# STM32MP25_CM33 register map
File version: 1.3
CPU: CM33 r0p1, little endian, MPU, FPU, vendor SysTick, 8 interrupt priority bits
Registers are 32-bit, read-write, reset 0x0 unless marked. A register's access mark holds for its fields unless they carry their own. Offsets are from the block's base; [hi:lo] are bit positions; {n}, {i} and the like mark numbered series; 'fields as' and 'values as' point back to an identical list.

## SYSCFG — SYSCFG register block
Base 0x44230000
Same registers: SYSCFG_S 0x54230000
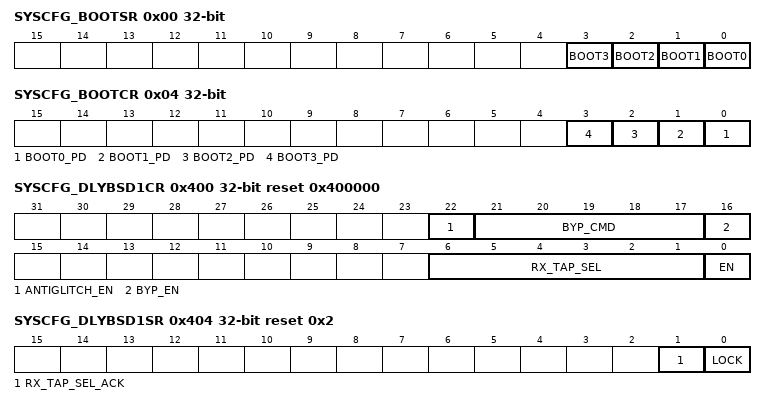
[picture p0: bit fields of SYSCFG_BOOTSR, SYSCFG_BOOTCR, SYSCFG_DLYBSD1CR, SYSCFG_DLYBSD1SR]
0x00 SYSCFG_BOOTSR ro (reset mask 0xFFFFFFF0) — SYSCFG boot pin status register
  [n] BOOT{n} (n=0..3) — BOOT{n} pin value
    0=low (BOOT{n} pin connected to VSS (or left open if BOOT{n}_PD = 0)); 1=high (BOOT{n} pin connected to VDD)
0x04 SYSCFG_BOOTCR — SYSCFG boot pin control register
  [all] fields
    0=enabled (pull-down enabled.); 1=disabled (pull-down disabled.)
  [n] BOOT{n}_PD (n=0..3) — BOOT{n} pin pull-down disable
0x400 SYSCFG_DLYBSD1CR reset 0x400000 — SYSCFG DLYBSD1 control register
  [22] ANTIGLITCH_EN
    1=The anti-glitch logic is enabled
  [21:17] BYP_CMD — Delay unit when in DLL bypass mode
    1=1 delay element enabled; 2=2 delay elements enabled; 24=all 24 delay elements enabled; 25=all 24 delay elements enabled; 31=all 24 delay elements enabled
  [16] BYP_EN — DLL bypass mode enable
    1=DLL bypass mode is enabled; 0=DLL lock mode is selected
  [6:1] RX_TAP_SEL — TAP number for RX clock selection
    0=0 tap selected; 1=1 tap is selected; 2=2 taps selected; 31=31 taps selected; 32=32 taps selected
  [0] EN — When 1, the DLL is enabled when configured in lock mode (BYP_EN = 0).
0x404 SYSCFG_DLYBSD1SR ro reset 0x2 — SYSCFG DLYBSD1 status register
  [1] RX_TAP_SEL_ACK
    1=The RX delay switched to the tap value specified in RX_TAP_SEL[5:0]
  [0] LOCK
    1=The DLL is locked
0x408 SYSCFG_SDMMC1CR — SYSCFG SDMMC1 control register
  [0] SDMMC1_VSEL — Voltage selection
    1=Change the voltage to low-voltage range (1; 0=Change the voltage to high-voltage range (3
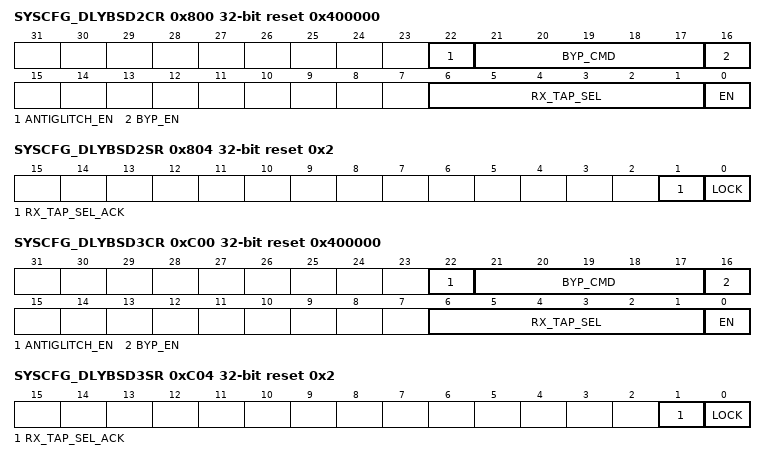
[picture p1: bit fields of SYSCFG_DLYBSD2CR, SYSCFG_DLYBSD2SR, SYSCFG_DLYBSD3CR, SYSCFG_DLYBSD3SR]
0x800 SYSCFG_DLYBSD2CR reset 0x400000 — SYSCFG DLYBSD2 control register
  [22] ANTIGLITCH_EN — Anti-glitch logic enable
    1=The anti-glitch logic is enabled
  [21:17] BYP_CMD — Delay unit when in DLL bypass mode
    values as SYSCFG_DLYBSD1CR.BYP_CMD
  [16] BYP_EN — DLL bypass mode enable
    1=DLL bypass mode is enabled; 0=DLL lock mode is selected
  [6:1] RX_TAP_SEL — TAP delay for RX clock selection
    0=0 tap selected; 1=1 tap selected; 2=2 taps selected; 31=31 taps selected; 32=32 taps selected
  [0] EN
    1=The DLL is enabled when configured in lock mode (BYP_EN = 0)
0x804 SYSCFG_DLYBSD2SR ro reset 0x2 — SYSCFG DLYBSD2 status register
  fields as SYSCFG_DLYBSD1SR
0x808 SYSCFG_SDMMC2CR — SYSCFG SDMMC2 control register
  [0] SDMMC2_VSEL — Voltage selection
    values as SYSCFG_SDMMC1CR.SDMMC1_VSEL
0xC00 SYSCFG_DLYBSD3CR reset 0x400000 — SYSCFG DLYBSD3 control register
  fields as SYSCFG_DLYBSD2CR
0xC04 SYSCFG_DLYBSD3SR ro reset 0x2 — SYSCFG DLYBSD3 status register
  [1] RX_TAP_SEL_ACK
    1=The RX delay has switched to the tap value specified in RX_TAP_SEL[5:0]
  [0] LOCK
    1=The DLL is locked
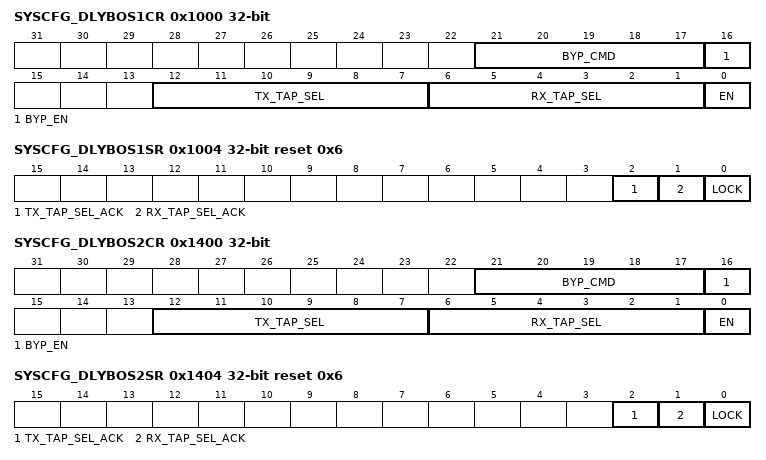
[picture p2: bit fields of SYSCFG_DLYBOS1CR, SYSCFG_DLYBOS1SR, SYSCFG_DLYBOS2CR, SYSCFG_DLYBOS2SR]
0x1000 SYSCFG_DLYBOS1CR — SYSCFG DLYBOS1 control register
  [21:17] BYP_CMD — Delay unit when in DLL bypass mode
    values as SYSCFG_DLYBSD1CR.BYP_CMD
  [16] BYP_EN — DLL bypass mode enable
    1=DLL bypass mode is enabled; 0=DLL lock mode is selected
  [12:7] TX_TAP_SEL — TAP delay for TX clock selection
    values as SYSCFG_DLYBSD2CR.RX_TAP_SEL
  [6:1] RX_TAP_SEL — TAP delay for RX clock selection
    values as SYSCFG_DLYBSD2CR.RX_TAP_SEL
  [0] EN
    values as SYSCFG_DLYBSD2CR.EN
0x1004 SYSCFG_DLYBOS1SR ro reset 0x6 — SYSCFG DLYBOS1 status register
  [2] TX_TAP_SEL_ACK
    1=The TX delay has switched to the tap value specified in TX_TAP_SEL[5:0]
  [1] RX_TAP_SEL_ACK
    values as SYSCFG_DLYBSD3SR.RX_TAP_SEL_ACK
  [0] LOCK
    1=The DLL is locked
0x1400 SYSCFG_DLYBOS2CR — SYSCFG DLYBOS2 control register
  [21:17] BYP_CMD — Delay unit when in DLL bypass mode
    values as SYSCFG_DLYBSD1CR.BYP_CMD
  [16] BYP_EN — DLL bypass mode enable
    1=DLL bypass mode is enabled; 0=DLL lock mode is selected
  [12:7] TX_TAP_SEL — TAP delay for TX clock selection
    values as SYSCFG_DLYBSD2CR.RX_TAP_SEL
  [6:1] RX_TAP_SEL — TAP delay for RX clock selection
    0=0 tap selected; 1=1 tap selected; 2=2 taps selected; 31=31 taps are selected; 32=32 taps are selected
  [0] EN — e
    values as SYSCFG_DLYBSD2CR.EN
0x1404 SYSCFG_DLYBOS2SR ro reset 0x6 — SYSCFG DLYBOS2 status register
  fields as SYSCFG_DLYBOS1SR
0x1800 SYSCFG_VDERAMCR — SYSCFG video decoder encoder RAM control register
  [0] VDERAM_EN — VDEC/VENC RAM enable
    0=VDERAM not allocated to the system; 1=VDERAM allocated to the system
0x1804 SYSCFG_POTTAMPRSTCR — SYSCFG potential tamper reset control register
  [0] POTTAMPRESETMASK — This bit can be set by software to mask PKA, SAES, CRYP1/2, and HASH reset in case of potential tamper.
    0=PKA, SAES, CRYP1/2, and HASH reset in case of potential tamper; 1=PKA, SAES, CRYP1/2, and HASH not reset in case of potential tamper
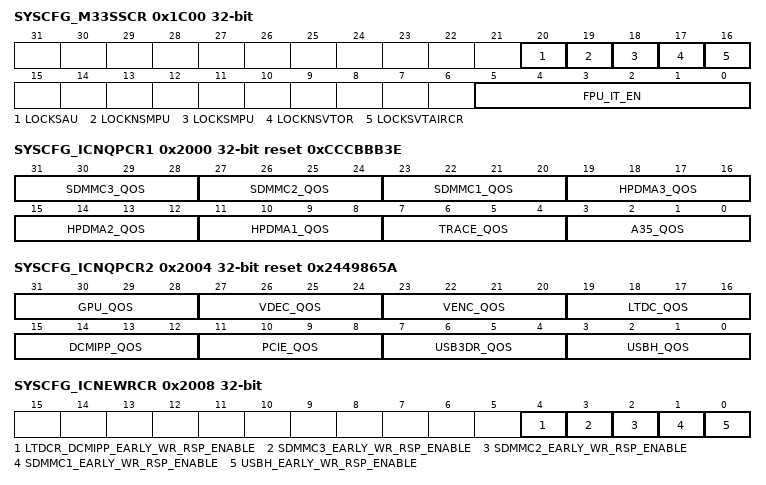
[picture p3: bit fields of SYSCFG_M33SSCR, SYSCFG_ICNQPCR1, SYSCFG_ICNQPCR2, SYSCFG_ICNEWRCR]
0x1C00 SYSCFG_M33SSCR — SYSCFG M33SS control register
  [20] LOCKSAU — Prevent changes to secure SAU memory regions already programmed.
  [19] LOCKNSMPU — Prevent changes to non-secure MPU memory regions already programmed.
  [18] LOCKSMPU — Prevent changes to programmed secure MPU memory regions.
  [17] LOCKNSVTOR — Prevent changes to non-secure vector table base address.
  [16] LOCKSVTAIRCR — Prevent changes to:
  [5:0] FPU_IT_EN — Floating point unit interrupt enable
0x2000 SYSCFG_ICNQPCR1 reset 0xCCCBBB3E — SYSCFG ICN QOS priority control register 1
  [all] fields
    0=Lowest priority; 15=Highest priority
  [31:28] SDMMC3_QOS — SDMMC3 read/write channel QoS setting
  [27:24] SDMMC2_QOS — SDMMC2 read/write channes QoS setting
  [23:20] SDMMC1_QOS — SDMMC1 read/write channel QoS setting
  [19:16] HPDMA3_QOS — HPDMA3 read/write channel QoS setting
  [15:12] HPDMA2_QOS — HPDMA2 read/write channel QoS setting
  [11:8] HPDMA1_QOS — HPDMA1 read/write channel QoS setting
  [7:4] TRACE_QOS — TRACE read/write channel QoS setting
  [3:0] A35_QOS — Cortex-A35 read/write channel QoS setting
0x2004 SYSCFG_ICNQPCR2 reset 0x2449865A — SYSCFG ICN QOS priority control register 2
  [all] fields
    0=Lowest priority; 15=Highest priority
  [31:28] GPU_QOS — GPU read/write channel QoS setting
  [27:24] VDEC_QOS — VDEC read/write channels QoS setting
  [23:20] VENC_QOS — VENC read/write channels QoS setting
  [19:16] LTDC_QOS — LTDC read/write channels QoS setting
  [15:12] DCMIPP_QOS — DCMIPP write channel QoS setting
  [11:8] PCIE_QOS — PCIE read/write channel QoS setting
  [7:4] USB3DR_QOS — USB3DR read/write channel QoS setting
  [3:0] USBH_QOS — USBH read/write channel QoS setting
0x2008 SYSCFG_ICNEWRCR — SYSCFG ICN early write response control register
  [all] fields
    0=Early write response disabled; 1=Early write response enabled
  [4] LTDCR_DCMIPP_EARLY_WR_RSP_ENABLE — LTDC Rotation and DCMIPP early write response enable
  [3] SDMMC3_EARLY_WR_RSP_ENABLE — SDMMC3 early write response enable
  [2] SDMMC2_EARLY_WR_RSP_ENABLE — SDMMC2 early write response enable
  [1] SDMMC1_EARLY_WR_RSP_ENABLE — SDMMC1 early write response enable
  [0] USBH_EARLY_WR_RSP_ENABLE — USBH (OHCI and EHCI) early write response enable
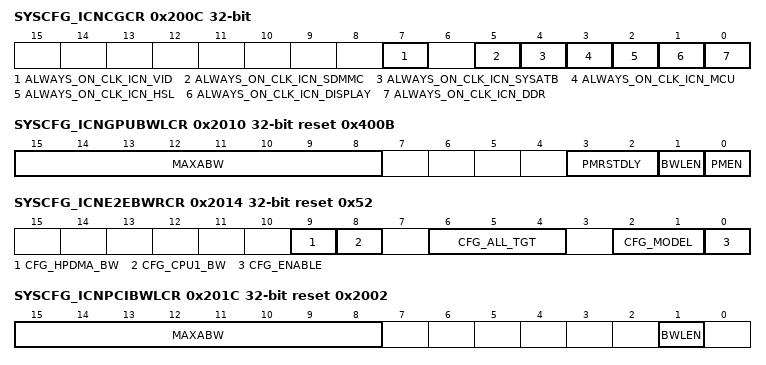
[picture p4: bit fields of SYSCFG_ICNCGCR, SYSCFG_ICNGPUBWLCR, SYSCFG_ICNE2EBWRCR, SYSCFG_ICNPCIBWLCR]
0x200C SYSCFG_ICNCGCR — SYSCFG ICN clock gating control register
  [7] ALWAYS_ON_CLK_ICN_VID — When set to 1, ICN automatic clock gating on clk_icn_vid domain is off.
  [5] ALWAYS_ON_CLK_ICN_SDMMC — When set to 1, ICN automatic clock gating on clk_icn_sdmmc domain is off.
  [4] ALWAYS_ON_CLK_ICN_SYSATB — When set to 1, ICN automatic clock gating on clk_icn_sysatb domain is off.
  [3] ALWAYS_ON_CLK_ICN_MCU — When set to 1, ICN automatic clock gating on clk_icn_mcu domain is off.
  [2] ALWAYS_ON_CLK_ICN_HSL — When set to 1, ICN automatic clock gating on clk_icn_hsl domain is off.
  [1] ALWAYS_ON_CLK_ICN_DISPLAY — When set to 1, ICN automatic clock gating on clk_icn_display domain is off.
  [0] ALWAYS_ON_CLK_ICN_DDR — When set to 1, ICN automatic clock gating on clk_icn_ddr domain is off.
0x2010 SYSCFG_ICNGPUBWLCR reset 0x400B — SYSCFG ICN GPU bandwidth limiter control register
  [15:8] MAXABW — Maximum allowed Bandwidth
    1=Bandwidth limited at 1/128 of 9
  [3:2] PMRSTDLY — Panic Mode Restart Delay
    0=No delay (immediate restart of flow); 1=16-cycle delay at DDR-CTRL frequency; 2=32-cycle delay at DDR-CTRL frequency; 3=64-cycle delay at DDR-CTRL frequency
  [1] BWLEN — Bandwidth limiter enable
    0=Bandwidth limiter disabled; 1=Bandwidth limiter enabled
  [0] PMEN — Panic Mode Enable
    0=DDR-to-GPU regulation disabled; 1=DDR-to-GPU regulation enabled
0x2014 SYSCFG_ICNE2EBWRCR reset 0x52 — SYSCFG ICN end-to-end bandwidth regulation control register
  [9] CFG_HPDMA_BW — Triple the bandwidth (BW) allowed to HPDMA1/2/3 by the regulation.
    0=Normal bandwidth allocated to HPDMA1/2/3; 1=Increased bandwidth allocated to HPDMA1/2/3
  [8] CFG_CPU1_BW — Triple the bandwidth allowed to the CPU1 by the regulation.
    values as CFG_HPDMA_BW
  [6:4] CFG_ALL_TGT — Amount of empty CAM slots in DDR-CTRL that the regulation targets
    0=9 empty slots targeted; 1=11 empty slots targeted; 2=13 empty slots targeted; 3=15 empty slots targeted; 4=17 empty slots targeted; 5=20 empty slots targeted (default); 6=24 empty slots targeted; 7=28 empty slots targeted
  [2:1] CFG_MODEL — Defines the reactivity of the regulation feedback.
    0=Slow reaction (risk of congestion if the regulation reacts too slow); 3=Fast reaction (risk of oscillation if the regulation reacts too fast)
  [0] CFG_ENABLE — Activates the end-to-end bandwidth regulation.
    0=Regulation disabled; 1=Regulation enabled
0x2018 SYSCFG_SAFERSTCR — SYSCFG safe reset control register
  [0] CFG_ENABLE — Activates the safe reset connector.
    0=Safe reset connector disabled; 1=Safe reset connector enabled
0x201C SYSCFG_ICNPCIBWLCR reset 0x2002 — SYSCFG ICN PCI bandwidth limiter control register
  [15:8] MAXABW — Maximum allowed Bandwidth
    1=Bandwidth limited at 1/128 of 2
  [1] BWLEN — Bandwidth limiter enable
    0=Bandwidth limiter disabled; 1=Bandwidth limiter enabled
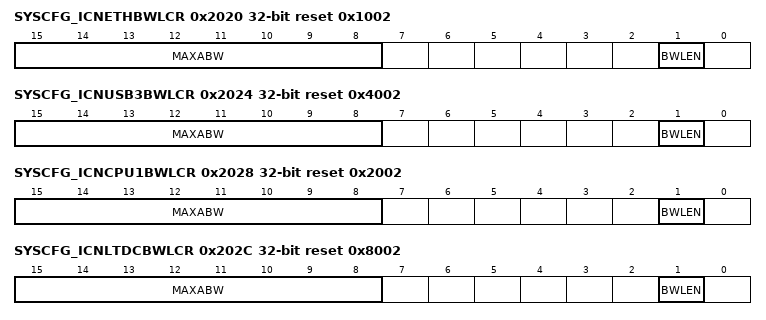
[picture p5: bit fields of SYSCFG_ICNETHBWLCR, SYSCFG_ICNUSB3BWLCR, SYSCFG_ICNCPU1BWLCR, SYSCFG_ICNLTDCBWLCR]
0x2020 SYSCFG_ICNETHBWLCR reset 0x1002 — SYSCFG ICN ETH bandwidth limiter control register
  fields as SYSCFG_ICNPCIBWLCR
0x2024 SYSCFG_ICNUSB3BWLCR reset 0x4002 — SYSCFG ICN USB3 bandwidth limiter control register
  fields as SYSCFG_ICNPCIBWLCR
0x2028 SYSCFG_ICNCPU1BWLCR reset 0x2002 — SYSCFG ICN CPU1 bandwidth limiter control register
  [15:8] MAXABW — Maximum allowed Bandwidth
    1=Bandwidth limited at 1/128 of 9
  [1] BWLEN — Bandwidth limiter enable
    0=Bandwidth limiter disabled; 1=Bandwidth limiter enabled
0x202C SYSCFG_ICNLTDCBWLCR reset 0x8002 — SYSCFG ICN LTDC bandwidth limiter control register
  [15:8] MAXABW — Maximum allowed Bandwidth
    1=Bandwidth limited at 1/128 of 3
  [1] BWLEN — Bandwidth limiter enable
    0=Bandwidth limiter disabled; 1=Bandwidth limiter enabled
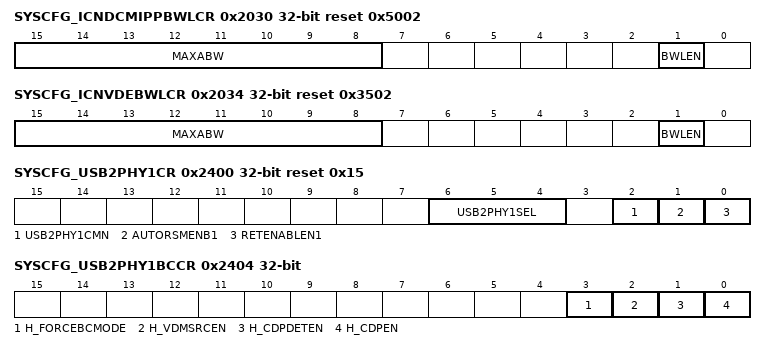
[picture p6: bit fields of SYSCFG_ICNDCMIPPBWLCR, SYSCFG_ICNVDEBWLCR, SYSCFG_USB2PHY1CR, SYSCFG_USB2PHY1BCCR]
0x2030 SYSCFG_ICNDCMIPPBWLCR reset 0x5002 — SYSCFG ICN DCMIPP bandwidth limiter control register
  fields as SYSCFG_ICNLTDCBWLCR
0x2034 SYSCFG_ICNVDEBWLCR reset 0x3502 — SYSCFG ICN Video Decoder Encoder bandwidth limiter control register
  [15:8] MAXABW — Maximum allowed Bandwidth
    1=Bandwidth limited at 1/128 of 4
  [1] BWLEN — Bandwidth limiter enable
    0=Bandwidth limiter disabled; 1=Bandwidth limiter enabled
0x2400 SYSCFG_USB2PHY1CR reset 0x15 — SYSCFG USB2PHY1 control register
  [6:4] USB2PHY1SEL — PHY reference clock speed setting
    0=19; 1=20 MHz (default); 2=24 MHz
  [2] USB2PHY1CMN — Controls power down of analog blocks during Suspend and Sleep.
    0=PHY clocks are kept active during Suspend and Sleep (with the exception of PHYCLK); 1=PHY clocks are off during Suspend and Sleep
  [1] AUTORSMENB1 — Auto-resume mode enable
    0=Auto-resume disabled (default; 1=A pulse on this bit prior to enabling the retention mode, enables the auto-resume mode
  [0] RETENABLEN1 — Retention mode enable (active low)
    0=Retention mode enabled; 1=Retention mode disabled (default)
0x2404 SYSCFG_USB2PHY1BCCR — SYSCFG USB2PHY1 battery charging control register
  [3] H_FORCEBCMODE — Forces USB2PHY1 in non-driving suspend mode.
    0=Normal mode; 1=OPMODE0[1:0] is forced to non-driving, and SUSPENDM0 is forced to active
  [2] H_VDMSRCEN — Voltage source on DM for CDP port enable
    0=Voltage source disabled (default); 1=Voltage source enabled
  [1] H_CDPDETEN — Voltage detector on DP for CDP port enable
    0=voltage detector on DP disabled (default); 1=voltage detector on DP enabled
  [0] H_CDPEN — CDP behavior for Host port enable
    0=CDP behavior disabled (Host port behaves as an SDP) (default); 1=CDP behavior enabled
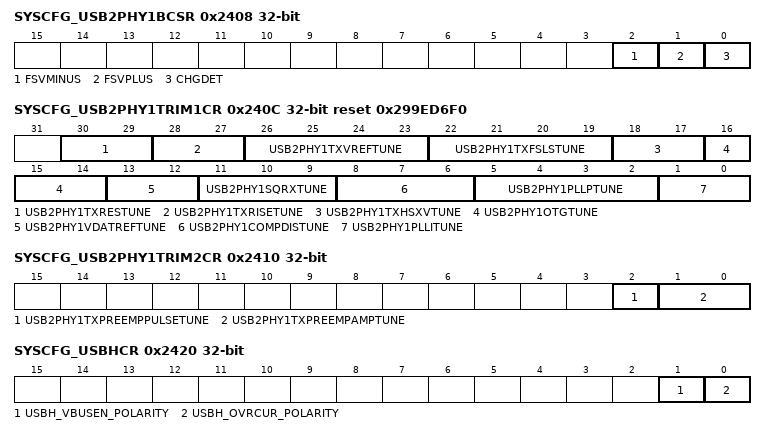
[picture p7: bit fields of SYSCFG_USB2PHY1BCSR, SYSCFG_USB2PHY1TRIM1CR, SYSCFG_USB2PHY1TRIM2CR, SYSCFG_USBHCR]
0x2408 SYSCFG_USB2PHY1BCSR ro — SYSCFG USB2PHY1 battery charging status register
  [2] FSVMINUS — Voltage level on DM (also output of the comparison with VLGC threshold, as defined in BC v1.
    0=VDM less than VLGC; 1=VDM > VLGC
  [1] FSVPLUS — Voltage level on DP (also output of the comparison with VLGC threshold, as defined in BC v1.
    0=VDP less than VLGC; 1=VDP > VLGC
  [0] CHGDET — Comparison of voltage on DP with VDAT_REF threshold as defined in BC v1.
    0=VDP less than VDAT_REF; 1=VDP > VDAT_REF
0x240C SYSCFG_USB2PHY1TRIM1CR reset 0x299ED6F0 — SYSCFG USB2PHY1 trimming 1 control register
  [30:29] USB2PHY1TXRESTUNE — USB source impedance adjustment
    3=Source impedance decreased by approximately 5; 2=Source impedance decreased by approximately 3; 1=Nominal; 0=Source impedance increased by approximately 1
  [28:27] USB2PHY1TXRISETUNE — High-speed transmitter rise/fall time adjustment
    3=-8; 2=-7; 1=Nominal; 0=+5
  [26:23] USB2PHY1TXVREFTUNE — HS DC voltage level adjustment
    15=+24%; 14=+22%; 13=+20%; 12=+18%; 11=+16%; 10=+14%; 9=+12%; 8=+10%; 7=+8%; 6=+6%; 5=+4%; 4=+2%; 3=Nominal; 2=-2%; 1=-4%; 0=-6%
  [22:19] USB2PHY1TXFSLSTUNE — Full-speed (FS)/low-speed (LS) source impedance adjustment
    15=-10; 7=-5; 3=Nominal; 1=+6; 0=+14%
  [18:17] USB2PHY1TXHSXVTUNE — Transmitter high-speed crossover adjustment
    3=Nominal; 2=+15 mV; 1=-15 mV
  [16:14] USB2PHY1OTGTUNE — Vless thansub>BUSless than/sub> valid threshold adjustment
    7=+12%; 6=+9%; 5=+6%; 4=+3%; 3=Nominal; 2=-3%; 1=-6%; 0=-9%
  [13:12] USB2PHY1VDATREFTUNE — Data detect voltage adjustment
    3=-20%; 2=-10%; 1=Nominal; 0=+10%
  [11:9] USB2PHY1SQRXTUNE — Squelch threshold adjustment
    7=-20%; 6=-15%; 5=-10%; 4=-5%; 3=Nominal; 2=+5%; 1=+10%; 0=+15%
  [8:6] USB2PHY1COMPDISTUNE — Disconnect threshold adjustment
    7=+12%; 6=+10%; 5=+7%; 4=+3%; 3=Nominal; 2=-4%; 1=-6%; 0=-9%
  [5:2] USB2PHY1PLLPTUNE — PLL proportional path tune
    15=5; 14=5x; 13=4; 12=4x; 11=4; 10=4x; 9=3; 8=3x; 7=3; 6=3x; 5=2; 4=2x; 3=2; 2=2x; 1=1; 0=1x
  [1:0] USB2PHY1PLLITUNE — PLL integral path tune
    3=2; 2=1; 1=1; 0=0
0x2410 SYSCFG_USB2PHY1TRIM2CR — SYSCFG USB2PHY1 trimming 2 control register
  [2] USB2PHY1TXPREEMPPULSETUNE — HS transmitter preemphasis duration control
    1=1x, short pre-emphasis current duration; 0=2x, long pre-emphasis current duration
  [1:0] USB2PHY1TXPREEMPAMPTUNE — HS transmitter preemphasis current control
    3=HS transmitter preemphasis circuit sources 3x preemphasis current; 2=HS transmitter preemphasis circuit sources 2x preemphasis current; 1=HS transmitter preemphasis circuit sources 1x preemphasis current; 0=HS transmitter preemphasis disabled
0x2420 SYSCFG_USBHCR — SYSCFG USBH control register
  [1] USBH_VBUSEN_POLARITY — Polarity of USBH_VBUSEN alternate function
    0=USBH_VBUSEN active high (a 1 logic level means VBUS must be enabled) (default); 1=USBH_VBUSEN active low (a 0 logic level means VBUS must be enabled)
  [0] USBH_OVRCUR_POLARITY — Polarity of USBH_OVRCUR alternate function
    0=USBH_OVRCUR active high (a 1 logic level means there is an over-current situation) (default); 1=USBH_OVRCUR active low (a 0 logic level means there is an over-current situation)
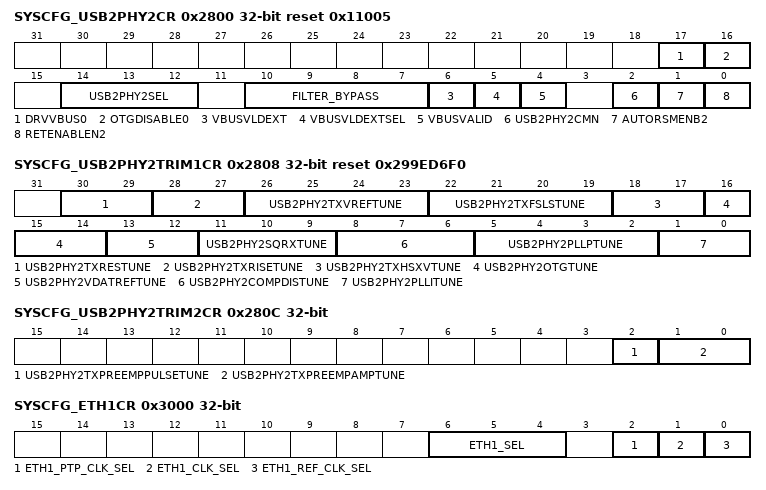
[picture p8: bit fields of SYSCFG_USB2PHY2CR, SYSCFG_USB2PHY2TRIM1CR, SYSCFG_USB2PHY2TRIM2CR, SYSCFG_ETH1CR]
0x2800 SYSCFG_USB2PHY2CR reset 0x11005 — SYSCFG USB2PHY2 control register
  [17] DRVVBUS0 — Control bit for VBUS valid comparator in USB2PHY2
    0=VBUS valid comparator is off in Suspend and Sleep modes (default); 1=VBUS valid comparator is on in Suspend and Sleep modes
  [16] OTGDISABLE0 — Disable control bit for VBUS valid comparator in USB2PHY2
    0=VBUS valid comparator is on in normal mode; 1=VBUS valid comparator is powered down
  [14:12] USB2PHY2SEL — PHY reference clock speed setting
    0=19; 1=20 MHz (default); 2=24 MHz
  [10:7] FILTER_BYPASS — Internal debounce logic enable (default)
    1=internal debounce logic disabled
  [6] VBUSVLDEXT — Voltage comparison result when an external voltage comparator is used
    0=VBUS not valid (default); 1=VBUS above valid threshold
  [5] VBUSVLDEXTSEL — VBUS valid comparator used when USB3DR controller is in device mode
    0=Session valid comparator inside USB2PHY2 is used (default); 1=An external voltage comparator is used
  [4] VBUSVALID — Control of VBUS valid input of USB3DR controller when in Host mode
    0=VBUS not valid (default); 1=VBUS above valid threshold
  [2] USB2PHY2CMN — Control of power down of analog blocks during Suspend and Sleep
    values as SYSCFG_USB2PHY1CR.USB2PHY1CMN
  [1] AUTORSMENB2 — Auto-resume mode enable
    0=Auto-resume is disabled (default); 1=A pulse on this bit prior to enabling the retention mode, enables the auto-resume mode
  [0] RETENABLEN2 — Retention mode enable (active low)
    values as SYSCFG_USB2PHY1CR.RETENABLEN1
0x2808 SYSCFG_USB2PHY2TRIM1CR reset 0x299ED6F0 — SYSCFG USB2PHY2 trimming 1 control register
  [30:29] USB2PHY2TXRESTUNE — USB source impedance adjustment
    values as SYSCFG_USB2PHY1TRIM1CR.USB2PHY1TXRESTUNE
  [28:27] USB2PHY2TXRISETUNE — HS transmitter rise/fall time adjustment
    3=-8; 2=-7; 1=Nominal; 0=+5
  [26:23] USB2PHY2TXVREFTUNE — HS DC voltage level adjustment
    values as SYSCFG_USB2PHY1TRIM1CR.USB2PHY1TXVREFTUNE
  [22:19] USB2PHY2TXFSLSTUNE — Full-speed (FS)/low-speed (LS) source impedance adjustment
    15=-10; 7=-5; 3=Nominal; 1=+6; 0=+14%
  [18:17] USB2PHY2TXHSXVTUNE — Transmitter HS crossover adjustment
    3=Nominal; 2=+15 mV; 1=-15 mV
  [16:14] USB2PHY2OTGTUNE — VBUS valid threshold adjustment
    7=+12%; 6=+9%; 5=+6%; 4=+3%; 3=Nominal; 2=-3%; 1=-6%; 0=-9%
  [13:12] USB2PHY2VDATREFTUNE — Data detect voltage adjustment
    3=-20%; 2=-10%; 1=Nominal; 0=+10%
  [11:9] USB2PHY2SQRXTUNE — Squelch threshold adjustment
    values as SYSCFG_USB2PHY1TRIM1CR.USB2PHY1SQRXTUNE
  [8:6] USB2PHY2COMPDISTUNE — Disconnect threshold adjustment
    7=+12%; 6=+10%; 5=+7%; 4=+3%; 3=Nominal; 2=-4%; 1=-6%; 0=-9%
  [5:2] USB2PHY2PLLPTUNE — PLL proportional path tune
    values as SYSCFG_USB2PHY1TRIM1CR.USB2PHY1PLLPTUNE
  [1:0] USB2PHY2PLLITUNE — PLL integral path tune
    3=2; 2=1; 1=1; 0=0
0x280C SYSCFG_USB2PHY2TRIM2CR — SYSCFG USB2PHY2 trimming 2 control register
  [2] USB2PHY2TXPREEMPPULSETUNE — HS transmitter preemphasis duration control
    1=1x, short preemphasis current duration; 0=2x, long preemphasis current duration
  [1:0] USB2PHY2TXPREEMPAMPTUNE — HS transmitter preemphasis current control
    3=HS transmitter preemphasis circuit sources 3x preemphasis current; 2=HS transmitter preemphasis circuit sources 2x preemphasis current; 1=HS transmitter preemphasis circuit sources 1x preemphasis current; 0=HS transmitter preemphasis is disabled
0x2C00 SYSCFG_OCTOSPIAMCR — SYSCFG OCTOSPI address mapping control register
  [2:0] OCTOSPI_ADDRESS_MAPPING — OCTOSPI1 and OCTOSPI2 address mapping
    0=OCTOSPI1 (256 Mbytes), OCTOSPI2 unmapped; 1=OCTOSPI1 (192 Mbytes), OCTOSPI2 (64 Mbytes); 2=OCTOSPI1 (128 Mbytes), OCTOSPI2 (128 Mbytes); 3=OCTOSPI1 (64 Mbytes), OCTOSPI2 (192 Mbytes)
0x3000 SYSCFG_ETH1CR — SYSCFG Ethernet1 control register
  [6:4] ETH1_SEL — Ethernet 1 PHY interface selection
    0=MII; 1=RGMII; 4=RMII
  [2] ETH1_PTP_CLK_SEL — PTP (IEEE1588) clock selection
    0=ETHSW ptp ref clock is used; 1=ck_ker_eth1ptp from the RCC is used
  [1] ETH1_CLK_SEL — RGMII 125 MHz clock selection
    0=External clock (ETH1_CLK125) is used; 1=Internal clock from the RCC is used
  [0] ETH1_REF_CLK_SEL — Ethernet reference/RX clock selection
    0=External clock is used; 1=Internal clock from the RCC is used
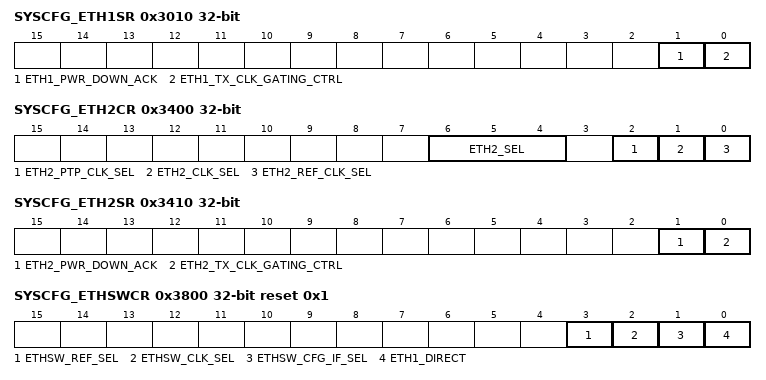
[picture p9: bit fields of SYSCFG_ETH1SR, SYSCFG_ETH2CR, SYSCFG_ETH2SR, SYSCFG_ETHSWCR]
0x3010 SYSCFG_ETH1SR ro — SYSCFG Ethernet1 status register
  [1] ETH1_PWR_DOWN_ACK — Asserted when the power-down sequence start has been acknowledged
  [0] ETH1_TX_CLK_GATING_CTRL — Asserted when the MAC has entered Tx LPI mode
0x3400 SYSCFG_ETH2CR — SYSCFG Ethernet2 configuration register
  [6:4] ETH2_SEL — Ethernet 2 PHY interface selection
    0=MII; 1=RGMII; 4=RMII
  [2] ETH2_PTP_CLK_SEL — PTP (IEEE1588) clock selection
    0=ETHSW ptp ref clock is used; 1=ck_ker_eth2ptp from the RCC is used
  [1] ETH2_CLK_SEL — RGMII 125MHz clock selection
    0=External clock (ETH2_CLK125) is used; 1=Internal clock from the RCC is used
  [0] ETH2_REF_CLK_SEL — Reference/RX clock selection
    values as SYSCFG_ETH1CR.ETH1_REF_CLK_SEL
0x3410 SYSCFG_ETH2SR ro — SYSCFG Ethernet2 status register
  [1] ETH2_PWR_DOWN_ACK — Asserted when the power-down sequence start has been acknowledged
  [0] ETH2_TX_CLK_GATING_CTRL — Asserted when the MAC has entered Tx LPI mode
0x3800 SYSCFG_ETHSWCR reset 0x1 — SYSCFG Ethernet switch configuration register
  [3] ETHSW_REF_SEL — Clock source selection for RMII 50 MHz
    0=External from ETH1_REF_CLK and ETH3_REF_CLK; 1=Internal from ck_ker_ethswref
  [2] ETHSW_CLK_SEL — Clock source selection for 125 MHz
    0=External from ETH1_CLK125 pin; 1=Internal from ck_ker_ethsw
  [1] ETHSW_CFG_IF_SEL — PHY interface type selection for external ports
    0=RMII; 1=RGMII
  [0] ETH1_DIRECT — Ethernet switch bypass
    0=Connect ETH1 to host port of ETHSW; 1=Connect ETH1 directly to PHY (bypass ETHSW)
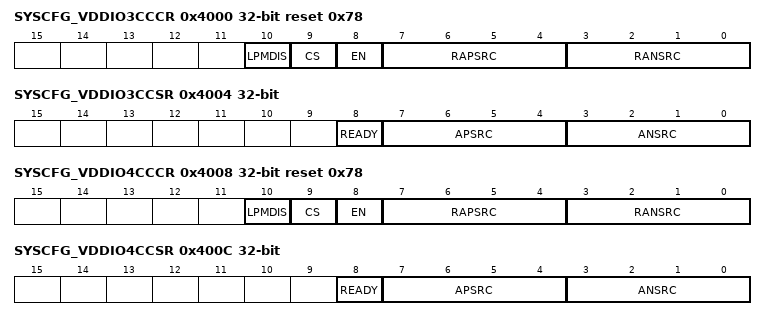
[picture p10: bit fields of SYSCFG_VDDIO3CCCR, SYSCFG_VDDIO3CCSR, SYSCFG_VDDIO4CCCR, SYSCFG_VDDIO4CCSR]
0x4000 SYSCFG_VDDIO3CCCR reset 0x78 — SYSCFG VDDIO3 compensation cell control register
  [10] LPMDIS — I/Os supplied by Vless thansub>DDIO3less than/sub> compensation cell low power mode disable
    0=Vless thansub>DDIO3less than/sub> I/O compensation is disabled by hardware when the system enters Stop, LP-Stop and LPLV-stop modes; 1=Vless thansub>DDIO3less than/sub> I/O compensation is not disabled by hardware when the system enters Stop, LP-Stop and LPLV-stop modes
  [9] CS — I/Os supplied by Vless thansub>DDIO3less than/sub> code selection
    0=Vless thansub>DDIO3less than/sub> I/O code from the cell (available in SYSCFG_VDDIO3CCSR); 1=Vless thansub>DDIO3less than/sub> I/O code from RANSRC[3:0] and RAPSRC[3:0] register values
  [8] EN — I/Os supplied by Vless thansub>DDIO3less than/sub> compensation cell enable
    0=Vless thansub>DDIO3less than/sub> I/Os compensation cell disabled; 1=Vless thansub>DDIO3less than/sub> I/Os compensation cell enabled
  [7:4] RAPSRC — PMOS compensation code of the I/Os supplied by Vless thansub>DDIO3less than/sub>
  [3:0] RANSRC — NMOS compensation code of the I/Os supplied by Vless thansub>DDIO3less than/sub>
0x4004 SYSCFG_VDDIO3CCSR ro — SYSCFG VDDIO3 compensation cell status register
  [8] READY — Vless thansub>DDIO3 less than/sub>I/O compensation cell ready flag
    0=Vless thansub>DDIO3 less than/sub>I/O compensation cell not ready; 1=Vless thansub>DDIO3 less than/sub>I/O compensation cell ready
  [7:4] APSRC — PMOS compensation value of the I/Os supplied by Vless thansub>DDIO3less than/sub>
  [3:0] ANSRC — NMOS compensation value of the I/Os supplied by Vless thansub>DDIO3less than/sub>
0x4008 SYSCFG_VDDIO4CCCR reset 0x78 — SYSCFG VDDIO4 compensation cell control register
  [10] LPMDIS — I/Os supplied by Vless thansub>DDIO4less than/sub> compensation cell low power mode disable
    0=Vless thansub>DDIO4less than/sub> I/O compensation is disabled by hardware when the system enters Stop, LP-Stop and LPLV-stop modes; 1=Vless thansub>DDIO4less than/sub> I/O compensation is not disabled by hardware when the system enters Stop, LP-Stop and LPLV-stop modes
  [9] CS — Vless thansub>DDIO4less than/sub> I/O code selection
    0=Vless thansub>DDIO4less than/sub> I/O code from the cell (available in SYSCFG_VDDIO4CCSR); 1=Vless thansub>DDIO4less than/sub> I/O code from RANSRC[3:0] and RAPSRC[3:0] values
  [8] EN — Vless thansub>DDIO4less than/sub> I/O compensation cell enable
    0=Vless thansub>DDIO4less than/sub> I/O compensation cell disabled; 1=Vless thansub>DDIO4less than/sub> I/O compensation cell enabled
  [7:4] RAPSRC — PMOS compensation code of the I/Os supplied by Vless thansub>DDIO4less than/sub>
  [3:0] RANSRC — NMOS compensation code of the I/Os supplied by Vless thansub>DDIO4less than/sub>
0x400C SYSCFG_VDDIO4CCSR ro — SYSCFG VDDIO4 compensation cell status register
  [8] READY — Vless thansub>DDIO4 less than/sub>I/O compensation cell ready flag
    0=Vless thansub>DDIO4 less than/sub>I/O compensation cell not ready; 1=Vless thansub>DDIO4 less than/sub>I/O compensation cell ready
  [7:4] APSRC — PMOS compensation value of the I/Os supplied by Vless thansub>DDIO4less than/sub>
  [3:0] ANSRC — NMOS compensation value of the I/Os supplied by Vless thansub>DDIO4less than/sub>
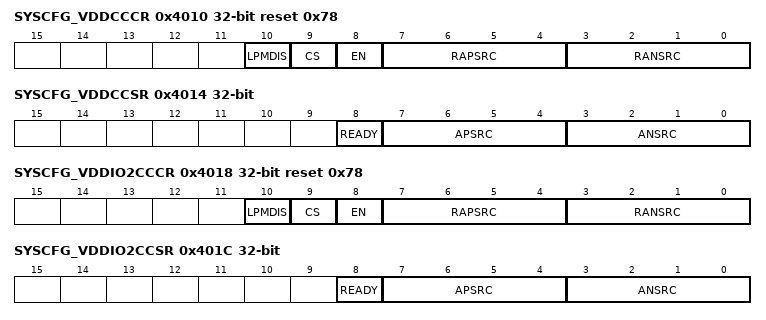
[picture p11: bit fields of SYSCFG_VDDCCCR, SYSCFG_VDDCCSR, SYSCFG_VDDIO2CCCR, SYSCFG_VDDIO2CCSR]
0x4010 SYSCFG_VDDCCCR reset 0x78 — SYSCFG VDD compensation cell control register
  [10] LPMDIS — I/Os supplied by Vless thansub>DDless than/sub> compensation cell low power mode disable
    0=Vless thansub>DDless than/sub> I/O compensation is disabled by hardware when the system enters Stop, LP-Stop and LPLV-stop modes; 1=Vless thansub>DDless than/sub> I/O compensation is not disabled by hardware when the system enters Stop, LP-Stop and LPLV-stop modes
  [9] CS — Vless thansub>DDless than/sub> I/O code selection
    0=Vless thansub>DDless than/sub> I/O code from the cell (available in SYSCFG_VDDCCSR); 1=Vless thansub>DDless than/sub> I/O code from RANSRC[3:0] and RAPSRC[3:0] values
  [8] EN — Vless thansub>DDless than/sub> I/O compensation cell enable
    0=Vless thansub>DDless than/sub> I/Os compensation cell disabled; 1=Vless thansub>DDless than/sub> I/Os compensation cell enabled
  [7:4] RAPSRC — PMOS compensation code of the I/Os supplied by Vless thansub>DDless than/sub>
  [3:0] RANSRC — NMOS compensation code of the I/Os supplied by Vless thansub>DDless than/sub>
0x4014 SYSCFG_VDDCCSR ro — SYSCFG VDD compensation cell status register
  [8] READY — Vless thansub>DD less than/sub>I/O compensation cell ready flag
    0=Vless thansub>DD less than/sub>I/O compensation cell not ready; 1=Vless thansub>DD less than/sub>I/O compensation cell ready
  [7:4] APSRC — PMOS compensation value of the I/Os supplied by Vless thansub>DDless than/sub>
  [3:0] ANSRC — NMOS compensation value of the I/Os supplied by Vless thansub>DDless than/sub>
0x4018 SYSCFG_VDDIO2CCCR reset 0x78 — SYSCFG VDDIO2 compensation cell control register
  [10] LPMDIS — I/Os supplied by Vless thansub>DDIO2less than/sub> compensation cell low power mode disable
    0=Vless thansub>DDIO2less than/sub> I/O compensation is disabled by hardware when the system enters Stop, LP-Stop and LPLV-stop modes; 1=Vless thansub>DDIO2less than/sub> I/O compensation is not disabled by hardware when the system enters Stop, LP-Stop and LPLV-stop modes
  [9] CS — Vless thansub>DDIO2less than/sub> I/O code selection
    0=Vless thansub>DDIO2less than/sub> I/O code from the cell (available in the SYSCFG_VDDIO2CCSR); 1=Vless thansub>DDIO2less than/sub> I/O code from RANSRC[3:0] and RAPSRC[3:0] register values
  [8] EN — Vless thansub>DDIO2less than/sub> I/O compensation cell enable
    0=Vless thansub>DDIO2less than/sub> I/O compensation cell disabled; 1=Vless thansub>DDIO2less than/sub> I/O compensation cell enabled
  [7:4] RAPSRC — PMOS compensation code of the I/Os supplied by Vless thansub>DDIO2less than/sub>
  [3:0] RANSRC — NMOS compensation code of the I/Os supplied by Vless thansub>DDIO2less than/sub>
0x401C SYSCFG_VDDIO2CCSR ro — SYSCFG VDDIO2 compensation cell status register
  [8] READY — Vless thansub>DDIO2 less than/sub>I/O compensation cell ready flag
    0=Vless thansub>DDIO2 less than/sub>I/O compensation cell not ready; 1=Vless thansub>DDIO2 less than/sub>I/O compensation cell ready
  [7:4] APSRC — PMOS compensation value of the I/Os supplied by Vless thansub>DDIO2less than/sub>
  [3:0] ANSRC — NMOS compensation value of the I/Os supplied by Vless thansub>DDIO2less than/sub>
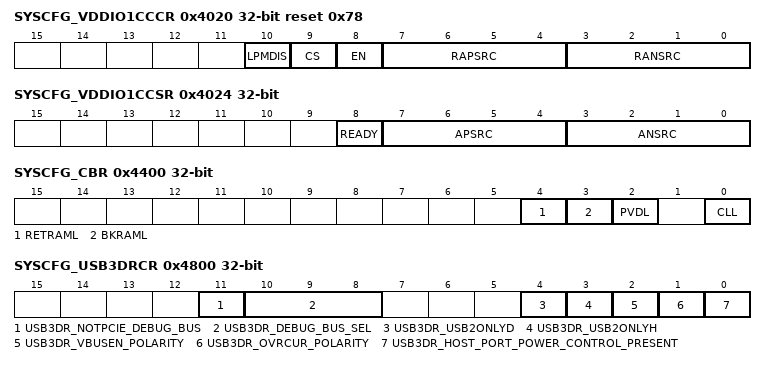
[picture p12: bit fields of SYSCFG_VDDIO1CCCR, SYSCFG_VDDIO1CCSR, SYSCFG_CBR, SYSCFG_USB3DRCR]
0x4020 SYSCFG_VDDIO1CCCR reset 0x78 — SYSCFG VDDIO1 compensation cell control register
  [10] LPMDIS — I/Os supplied by Vless thansub>DDIO1less than/sub> compensation cell low power mode disable
    0=Vless thansub>DDIO1less than/sub> I/O compensation is disabled by hardware when the system enters Stop, LP-Stop and LPLV-stop modes; 1=Vless thansub>DDIO1less than/sub> I/O compensation is not disabled by hardware when the system enters Stop, LP-Stop and LPLV-stop modes
  [9] CS — Vless thansub>DDIO1less than/sub> I/O code selection
    0=Vless thansub>DDIO1less than/sub> I/O code from the cell (available in SYSCFG_VDDIO1CCSR); 1=Vless thansub>DDIO1less than/sub> I/O code from RANSRC[3:0] and RAPSRC[3:0] values
  [8] EN — Vless thansub>DDIO1less than/sub> I/O compensation cell enable
    0=Vless thansub>DDIO1less than/sub> I/O compensation cell disabled; 1=Vless thansub>DDIO1less than/sub> I/O compensation cell enabled
  [7:4] RAPSRC — PMOS compensation code of the I/Os supplied by Vless thansub>DDIO1less than/sub>
  [3:0] RANSRC — NMOS compensation code of the I/Os supplied by Vless thansub>DDIO1less than/sub>
0x4024 SYSCFG_VDDIO1CCSR ro — SYSCFG VDDIO1 compensation cell status register
  [8] READY — Vless thansub>DDIO1 less than/sub>I/O compensation cell ready flag
    0=Vless thansub>DDIO1 less than/sub>I/O compensation cell not ready; 1=Vless thansub>DDIO1 less than/sub>I/O compensation cell ready
  [7:4] APSRC — PMOS compensation value of the I/Os supplied by Vless thansub>DDIO1less than/sub>
  [3:0] ANSRC — NMOS compensation value of the I/Os supplied by Vless thansub>DDIO1less than/sub>
0x4400 SYSCFG_CBR rw-once — SYSCFG control timer break register
  [4] RETRAML — RETRAM double ECC error lock
    0=RETRAM double ECC error signal disconnected from TIM1/8/15/16/17/20 break inputs; 1=RETRAM double ECC error signal connected to TIM1/8/15/16/17/20 break inputs
  [3] BKRAML — BKPSRAM double ECC error lock
    0=BKPSRAM double ECC error signal disconnected from TIM1/8/15/16/17/20 break inputs; 1=BKPSRAM double ECC error signal connected to TIM1/8/15/16/17/20 break inputs
  [2] PVDL — PVD lock enable
    0=PVD interrupt disconnected from TIM1/8/15/16/17 break input; 1=PVD interrupt connected to TIM1/8/15/16/17 break input
  [0] CLL — Cortex-M33 LOCKUP (HardFault) output enable
    0=Cortex-M33 LOCKUP output disconnected from TIM1/8/15/16/17 break inputs; 1=Cortex-M33 LOCKUP output connected to TIM1/8/15/16/17 break inputs
0x4800 SYSCFG_USB3DRCR — SYSCFG USB3DR control register
  [11] USB3DR_NOTPCIE_DEBUG_BUS — Selection of USB3DR or PCIE debug signals
    0=PCIE debug signals are selected; 1=USB3DR debug signals are selected
  [10:8] USB3DR_DEBUG_BUS_SEL — Selection of USB3DR/USBH debug signals
    0=usb3dr_logic_analyzer[15:0]; 1=usb3dr_logic_analyzer[31:16]; 2=usb3dr_logic_analyzer[47:32]; 3=usb3dr_logic_analyzer[63:48]
  [4] USB3DR_USB2ONLYD
    0=USB3DR controller used in USB3 mode; 1=USB3DR controller used in USB2-only Device mode
  [3] USB3DR_USB2ONLYH
    0=USB3DR controller used in USB3 mode; 1=USB3DR controller used in USB2-only Host mode
  [2] USB3DR_VBUSEN_POLARITY — Polarity of USB3DR_VBUSEN alternate function
    0=USB3DR_VBUSEN active high (a 1 logic level means the VBUS must be enabled) (default); 1=USB3DR_VBUSEN active low (a 0 logic level means the VBUS must be enabled)
  [1] USB3DR_OVRCUR_POLARITY — Polarity of USB3DR_OVRCUR alternate function
    0=USB3DR_OVRCUR active high (a 1 logic level means there is an over-current situation) (default); 1=USB3DR_OVRCUR active low (a 0 logic level means there is an over-current situation)
  [0] USB3DR_HOST_PORT_POWER_CONTROL_PRESENT — This port defines the bit[3] of capability parameters (HCCPARAMS).
    0=Indicates that the port does not have port power switches; 1=Indicates that the port has port power switches
0x4804 SYSCFG_USB3DRSR ro — SYSCFG USB3DR status register
  [2:0] USB3DR_CLK_GATE_CTRL — USB3DR debug register - Clock gating control
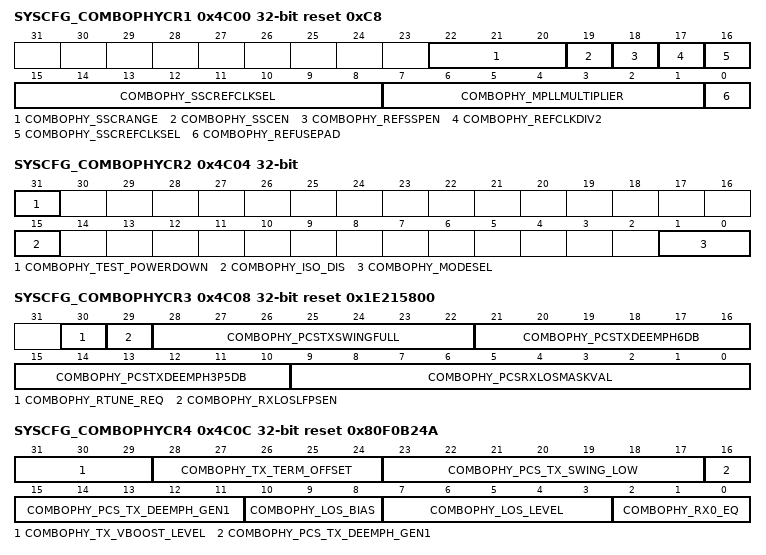
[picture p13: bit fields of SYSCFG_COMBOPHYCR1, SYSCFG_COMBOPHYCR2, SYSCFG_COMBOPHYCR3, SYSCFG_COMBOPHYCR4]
0x4C00 SYSCFG_COMBOPHYCR1 reset 0xC8 — SYSCFG COMBOPHY control register 1
  [22:20] COMBOPHY_SSCRANGE — Selection of the range of spread-spectrum modulation
    0=-4980 ppm; 1=-4492 ppm; 2=-4003 ppm; 3=-2000 ppm; 4=4980 ppm; 5=4492 ppm; 6=4003 ppm; 7=2000 ppm
  [19] COMBOPHY_SSCEN — Spread-spectrum enable
    0=Spread-spectrum disabled; 1=Spread-spectrum enabled (modulation at approximately 31
  [18] COMBOPHY_REFSSPEN — Reference clock enable
    0=Reference clock buffer disabled; 1=Reference clock buffer enabled
  [17] COMBOPHY_REFCLKDIV2 — Parameter for the frequency selection of the reference clock
    0=19; 1=40 or 200 MHz
  [16:8] COMBOPHY_SSCREFCLKSEL — Parameter for reference clock frequency selection
    0=20, 25, 40, 50, 100, or 200 MHz; 0x108=19
  [7:1] COMBOPHY_MPLLMULTIPLIER — Parameter for reference clock frequency selection
    2=19; 25=100 or 200 MHz; 48=52 MHz; 50=50 MHz; 52=48 MHz; 65=38; 96=26 MHz; 100=25 MHz; 104=24 MHz; 125=20 or 40 MHz
  [0] COMBOPHY_REFUSEPAD — Selection of COMBOPHY reference clock source
    0=Reference clock sourced either from RCC or directly from HSE (depending on USB3PCIEPHYCKREFSEL in RCC_USB3PCIEPHYCFGR); 1=Reference clock sourced from PCIE_CLKIN_P/N pins
0x4C04 SYSCFG_COMBOPHYCR2 — SYSCFG COMBOPHY control register 2
  [31] COMBOPHY_TEST_POWERDOWN — Forces the entire PHY into its lowest power state by turning everything off.
  [15] COMBOPHY_ISO_DIS — COMBOPHY isolation cells disable
    0=Electrical isolation for signals between Vless thansub>DDCOREless than/sub> and Vless thansub>DDCOMBOPHYless than/sub> is enabled; 1=Electrical isolation for signals between Vless thansub>DDCOREless than/sub> and Vless thansub>DDCOMBOPHYless than/sub> is disabled
  [1:0] COMBOPHY_MODESEL — COMBOPHY mode selection
    0=PCIE; 3=USB3
0x4C08 SYSCFG_COMBOPHYCR3 reset 0x1E215800 — SYSCFG COMBOPHY control register 3
  [30] COMBOPHY_RTUNE_REQ — Instructs COMBOPHY to perform a termination calibration.
    0=Idle; 1=A termination calibration must be performed by the COMBOPHY
  [29] COMBOPHY_RXLOSLFPSEN — Enables the RX LOS LFPS mode.
  [28:22] COMBOPHY_PCSTXSWINGFULL — TX amplitude (full swing mode)
  [21:16] COMBOPHY_PCSTXDEEMPH6DB — TX deemphasis at 6 dB (USB3 use case)
  [15:10] COMBOPHY_PCSTXDEEMPH3P5DB — TX deemphasis at 3.
  [9:0] COMBOPHY_PCSRXLOSMASKVAL — Masks the incoming LFPS for the number of reference clock cycles equal to the value of this bit field.
0x4C0C SYSCFG_COMBOPHYCR4 reset 0x80F0B24A — SYSCFG COMBOPHY control register 4
  [31:29] COMBOPHY_TX_VBOOST_LEVEL — TX voltage boost level
    3=Launch amplitude of 0; 4=Launch amplitude of 1 V; 5=Launch amplitude of 1
  [28:24] COMBOPHY_TX_TERM_OFFSET — Transmitter termination offset
  [23:17] COMBOPHY_PCS_TX_SWING_LOW — TX amplitude (low swing mode) (PCIE use case)
  [16:11] COMBOPHY_PCS_TX_DEEMPH_GEN1 — TX deemphasis at 3.
  [10:8] COMBOPHY_LOS_BIAS — Loss-of-signal detector threshold level control
  [7:3] COMBOPHY_LOS_LEVEL — Loss-of-signal detector sensitivity level control
  [2:0] COMBOPHY_RX0_EQ — RX equalizer setting
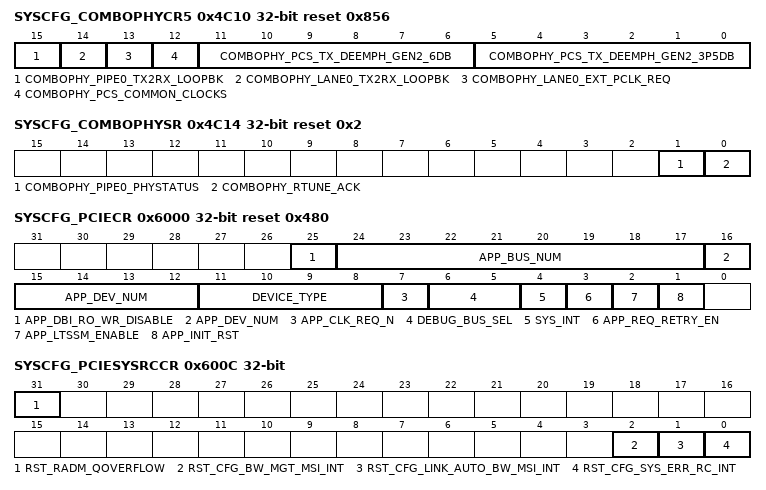
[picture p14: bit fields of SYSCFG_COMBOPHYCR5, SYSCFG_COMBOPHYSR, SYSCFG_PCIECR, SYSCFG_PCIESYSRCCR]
0x4C10 SYSCFG_COMBOPHYCR5 reset 0x856 — SYSCFG COMBOPHY control register 5
  [15] COMBOPHY_PIPE0_TX2RX_LOOPBK — PCIE use case
  [14] COMBOPHY_LANE0_TX2RX_LOOPBK — USB3 use case
  [13] COMBOPHY_LANE0_EXT_PCLK_REQ — USB3 use case
  [12] COMBOPHY_PCS_COMMON_CLOCKS — Common clock mode selection for PCIE receive data path
    0=Reference clock not common; 1=Common reference clock
  [11:6] COMBOPHY_PCS_TX_DEEMPH_GEN2_6DB — TX deemphasis at 6 dB (PCIE gen2 use case)
  [5:0] COMBOPHY_PCS_TX_DEEMPH_GEN2_3P5DB — TX deemphasis at 3.
0x4C14 SYSCFG_COMBOPHYSR ro reset 0x2 — SYSCFG COMBOPHY status register
  [1] COMBOPHY_PIPE0_PHYSTATUS — Communicates completion of several PHY functions.
    0=When COMBOPHY reset is deasserted, and the COMBOPHY PLL and PIPE clock runs; 1=While the COMBOPHY reset is asserted
  [0] COMBOPHY_RTUNE_ACK — End of the termination calibration step
    0=Idle; 1=Termination calibration has completed
0x5000 SYSCFG_DISPLAYCLKCR reset 0x1 — SYSCFG display clock control register
  [1:0] PIXEL_CLK_SEL — Control of pixel clock output selection
    0=Select DSI clock from the DSI PLL; 1=Select LVDS clock from the LVDS PLL; 2=Select ck_ker_ltdc clock (for parallel or DSI displays)
0x6000 SYSCFG_PCIECR reset 0x480 — SYSCFG PCIE control register
  [25] APP_DBI_RO_WR_DISABLE — DBI read-only write disable
    0=DBI_RO_WR_EN in PCIE_PORT_LOGIC_MISC_CONTROL_1_OFF is read-write and can be used to enable write access to some read-only registers; 1=DBI_RO_WR_EN is forced to 0 and is read-only
  [24:17] APP_BUS_NUM — Bus number in the requester ID for RC port
  [16:12] APP_DEV_NUM — Device number in the requester ID for an RC port
  [11:8] DEVICE_TYPE — Device/port type
    0=PCI express endpoint; 1=Legacy PCI express endpoint; 4=Root port of PCI express root complex
  [7] APP_CLK_REQ_N — Clear this bit to 0 if the application does not want to remove the reference clock.
  [6:5] DEBUG_BUS_SEL — Selection of PCIE observation points
  [4] SYS_INT — When pcie_sys_int goes from low to high, the PCIE controller generates an Assert_INTx message.
  [3] APP_REQ_RETRY_EN — Provides a capability to defer incoming configuration requests until initialization is complete (only for endpoint).
  [2] APP_LTSSM_ENABLE — After application has finished initializing the core configuration registers, it must assert this bit to allow the LTSSM to continue link establishment.
  [1] APP_INIT_RST — Requests from the application to send a hot reset to the downstream device (only for RootComplex).
0x6004 SYSCFG_PCIEPMEMSICR — SYSCFG PCIE CFG_PME_MSI control register
  [0] RST_CFG_PME_MSI_INT — Reset pcie_cfg_pme_msi interrupt logic
    0=Reset inactive; 1=Reset active
0x6008 SYSCFG_PCIEAERRCMSICR — SYSCFG PCIE CFG_AER_RC_ERR_MSI control register
  [0] RST_CFG_AER_RC_ERR_MSI_INT — Reset pcie_cfg_aer_rc_err_msi interrupt logic
    0=Reset inactive; 1=Reset active
0x600C SYSCFG_PCIESYSRCCR — SYSCFG PCIE CFG_SYS_ERR_RC control register
  [all] fields
    0=Reset inactive; 1=Reset active
  [31] RST_RADM_QOVERFLOW — Reset radm_qoverflow interrupt logic
  [2] RST_CFG_BW_MGT_MSI_INT — Reset cfg_bw_mgt_msi interrupt logic
  [1] RST_CFG_LINK_AUTO_BW_MSI_INT — Reset cfg_link_auto_bw_msi interrupt logic
  [0] RST_CFG_SYS_ERR_RC_INT — Reset pcie_cfg_sys_err_rc interrupt logic
0x6010 SYSCFG_PCIEPTMIRQCR — SYSCFG PCIE PTM interrupt control register
  [all] fields
    0=Reset inactive; 1=Reset active
  [3] RST_PTM_REQ_REPLAY_TX — Reset ptm_req_replay_rx interrupt logic
  [2] RST_PTM_REQ_DUP_RX — Reset ptm_req_dup_rx interrupt logic
  [1] RST_PTM_REQ_RESPONSE_TIMEOUT — Reset ptm_req_response_timeout interrupt logic
  [0] RST_PTM_CLOCK_UPDATED — Reset ptm_clock_updated interrupt logic
0x6080 SYSCFG_PCIEPRGCR reset 0x6 — SYSCFG PCIE PRG control register
  [5:1] PRG_IMP_CTRL — Control of the impedance of the 100 MHz differential output buffer
  [0] PRG_EN
    0=The internal 100 MHz clock PCIe Reference Generator is disabled; 1=The internal 100 MHz clock PCIe Reference Generator is enabled
0x6100 SYSCFG_PCIESR1 ro reset 0x4 — SYSCFG PCIE status register 1
  [21] PTM_RESPONDER_RDY_TO_VALIDATE — Application software can re-validate the context, because it was invalidated.
  [20] PTM_UPDATING — PTM update in progress
  [19] PTM_CLOCK_UPDATED — Controller updated the local clock.
  [18] PTM_REQ_RESPONSE_TIMEOUT — PTM requester response timeout
  [17] PTM_REQ_DUP_RX — PTM requester duplicate TLP received
  [16] PTM_REQ_REPLAY_TX — PTM requester detected a TLP replay being sent when responseD message in use, and one of the following:
  [15] RADM_QOVERFLOW — Level high indicates that one or more of the P/NP/CPL receive queues has overflowed.
  [14] RADM_Q_NOT_EMPTY — Level high indicates that the receive queues contain TLP header/data.
  [13] CFG_AER_RC_ERR_INT — pcie_1_cfg_aer_rc_err interrupt
  [12] CFG_PME_INT — pcie_1_cfg_pme interrupt
  [11] INTA_INTERRUPT — pcie_1_inta interrupt
  [10] INTB_INTERRUPT — pcie_1_intb interrupt
  [9] INTC_INTERRUPT — pcie_1_intc interrupt
  [8] INTD_INTERRUPT — pcie_1_intd interrupt
  [6] MSI_CTRL_INT — pcie_1_msi_ctrl_int interrupt
  [5] RDLH_LINK_UP — Data link layer up, status for RC application
  [4] CFG_HW_AUTO_SP_DIS — Hardware autonomous speed disable
  [3] SMLH_LINK_UP — PHY link up, status for RC application
  [2:0] PM_DSTATE — Power management D-state
0x6104 SYSCFG_PCIESR2 ro — SYSCFG PCIE interrupt status register 2
  [2] CFG_SYS_ERR_RC_INT_STS — Status of PCIE cfg_sys_err_rc interrupt
  [1] CFG_AER_RC_ERR_MSI_INT_STS — Status of PCIE cfg_aer_rc_err_msi interrupt
  [0] CFG_PME_MSI_INT_STS — Status of PCIE cfg_pme_msi interrupt
0x6400 SYSCFG_IDC ro reset 0x20006505 — SYSCFG device ID register
  [31:16] MAJOR_REV_ID — Device revision
  [11:0] DEV_ID — Device ID
    0x505=STM32MP25xx
0x7FF4 SYSCFG_VERR ro reset 0x11 — SYSCFG version register
  [7:4] MAJREV — SYSCFG major revision
  [3:0] MINREV — SYSCFG minor revision
0x7FF8 SYSCFG_IPIDR ro reset 0x30003 — SYSCFG identification register
  [31:0] ID — SYSCFG identifier
0x7FFC SYSCFG_SIDR ro reset 0xA3C5DD40 — SYSCFG size identification register
  [31:0] SID — Size identification
